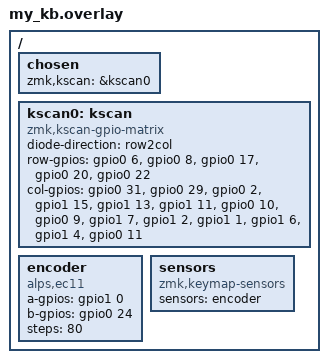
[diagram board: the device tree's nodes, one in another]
/ {
    chosen {
        zmk,kscan = &kscan0;
    };

    kscan0: kscan {
        compatible = "zmk,kscan-gpio-matrix";
        diode-direction = "row2col";
        row-gpios
            = <&gpio0 6  (GPIO_ACTIVE_HIGH | GPIO_PULL_DOWN)>
            , <&gpio0 8  (GPIO_ACTIVE_HIGH | GPIO_PULL_DOWN)>
            , <&gpio0 17 (GPIO_ACTIVE_HIGH | GPIO_PULL_DOWN)>
            , <&gpio0 20 (GPIO_ACTIVE_HIGH | GPIO_PULL_DOWN)>
            , <&gpio0 22 (GPIO_ACTIVE_HIGH | GPIO_PULL_DOWN)>
            ;
        col-gpios
            = <&gpio0 31 GPIO_ACTIVE_HIGH>
            , <&gpio0 29 GPIO_ACTIVE_HIGH>
            , <&gpio0 2  GPIO_ACTIVE_HIGH>
            , <&gpio1 15 GPIO_ACTIVE_HIGH>
            , <&gpio1 13 GPIO_ACTIVE_HIGH>
            , <&gpio1 11 GPIO_ACTIVE_HIGH>
            , <&gpio0 10 GPIO_ACTIVE_HIGH>
            , <&gpio0 9  GPIO_ACTIVE_HIGH>
            , <&gpio1 7  GPIO_ACTIVE_HIGH>
            , <&gpio1 2  GPIO_ACTIVE_HIGH>
            , <&gpio1 1  GPIO_ACTIVE_HIGH>
            , <&gpio1 6  GPIO_ACTIVE_HIGH>
            , <&gpio1 4  GPIO_ACTIVE_HIGH>
            , <&gpio0 11 GPIO_ACTIVE_HIGH>
            ;
    };

    encoder: encoder {
        compatible = "alps,ec11";
        a-gpios = <&gpio1 0 (GPIO_ACTIVE_HIGH | GPIO_PULL_UP)>;
        b-gpios = <&gpio0 24 (GPIO_ACTIVE_HIGH | GPIO_PULL_UP)>;
        steps = <80>;
    };

    sensors {
        compatible = "zmk,keymap-sensors";
        sensors = <&encoder>;
    };
};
